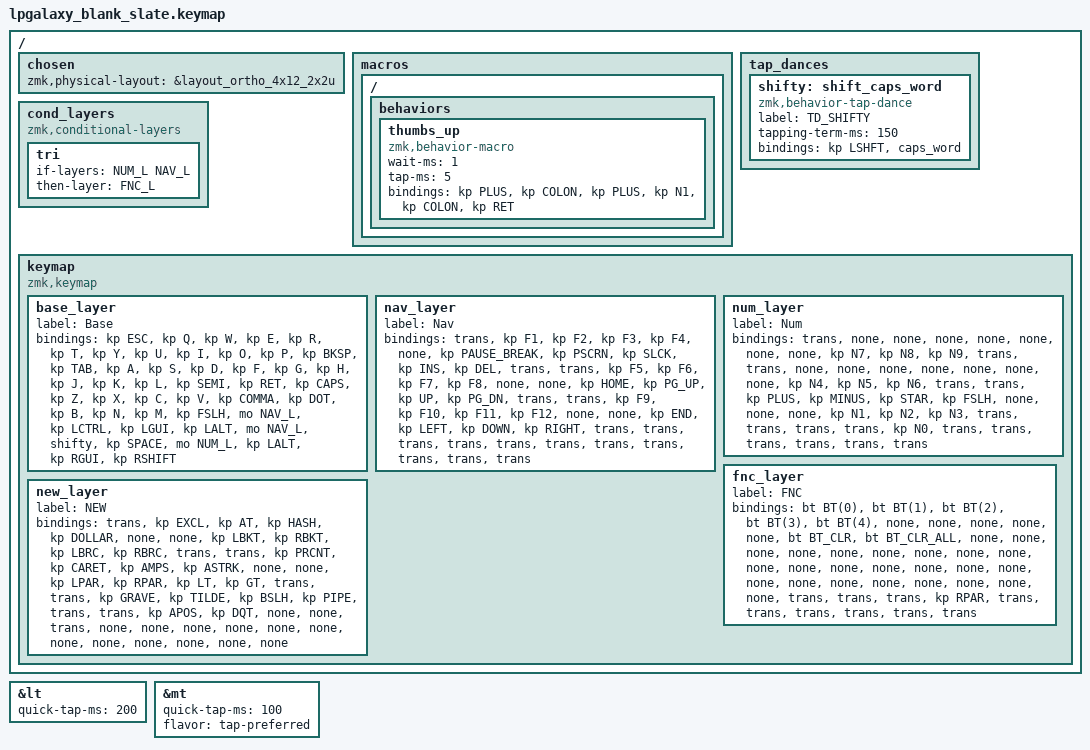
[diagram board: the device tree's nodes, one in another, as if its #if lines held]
/*
 * Copyright (c) 2022 Pete Johanson
 *
 * SPDX-License-Identifier: MIT
 */

#include <behaviors.dtsi>
#include <dt-bindings/zmk/keys.h>
#include <dt-bindings/zmk/bt.h>
#include <dt-bindings/zmk/outputs.h>

#define QWERTY_BASE 1

#define TBLE_ORTHO   1
// #define TBLE_MIT     1
// #define TBLE_DUAL_2U 1

#define NAV_L 1
#define NUM_L 2
#define FNC_L 3
#define NEW_L 4


// Using layer taps on thumbs, having quick tap as well helps w/ repeating space/backspace
&lt { quick-tap-ms = <200>; };
&mt { quick-tap-ms = <100>; flavor = "tap-preferred"; };

#define BT(n) BT_SEL n

/ {
    chosen {
       zmk,physical-layout =
#ifdef TBLE_DUAL_2U
                       &layout_ortho_4x12_2x2u;
#elif defined(TBLE_MIT)
                       &layout_ortho_4x12_1x2u;
#else
                       &layout_ortho_4x12_all1u;
#endif
    };

    macros {
      ZMK_MACRO(thumbs_up,
		wait-ms = <1>;
		tap-ms = <5>;
                bindings = <&kp PLUS &kp COLON &kp PLUS &kp N1 &kp COLON &kp RET>;
		)
    };
    
    tap_dances {
    	shifty: shift_caps_word {
		compatible = "zmk,behavior-tap-dance";
		label = "TD_SHIFTY";
		#binding-cells = <0>;
		tapping-term-ms = <150>;
		bindings = <&kp LSHFT>, <&caps_word>;
	};
    };


// Conditional layer only when we have less thumb keys
#ifdef TBLE_DUAL_2U
    cond_layers {
        compatible = "zmk,conditional-layers";
	tri {
	    if-layers = <NUM_L NAV_L>;
	    then-layer = <FNC_L>;
        };
    };
#endif

    keymap {
        compatible = "zmk,keymap";

        base_layer {
            label = "Base";
            bindings = <
#ifdef QWERTY_BASE 
		 &kp ESC    &kp Q      &kp W      &kp E     &kp R    &kp T       &kp Y     &kp U     &kp I      &kp O    &kp P       &kp BKSP     
		 &kp TAB    &kp A      &kp S      &kp D     &kp F    &kp G       &kp H     &kp J     &kp K      &kp L    &kp SEMI    &kp RET
		 &kp CAPS   &kp Z      &kp X      &kp C     &kp V    &kp COMMA   &kp DOT   &kp B     &kp N      &kp M    &kp FSLH    &mo NAV_L
#else
 &kp ESC    &kp Q      &kp W      &kp F       &kp P          &kp B          &kp J            &kp L          &kp U       &kp Y      &kp QUOT      &kp BKSP
 &kp TAB    &kp A      &kp R      &kp S       &kp T          &kp G          &kp M            &kp N          &kp E       &kp I      &kp O         &kp QUOT
 &kp LSHFT  &kp Z      &kp X      &kp C       &kp D          &kp V          &kp K            &kp H          &kp COMMA   &kp DOT    &kp SEMI      &kp RET
#endif
#ifdef TBLE_DUAL_2U
 &kp LCTRL  &kp LGUI   &kp LALT   &mo NAV_L         &shifty                        &kp SPACE                &mo NUM_L   &kp LALT   &kp RGUI      &kp RSHIFT
#elif defined(TBLE_MIT)
 &kp LCTRL  &mo FNC_L   &kp LGUI  &kp LALT    &mo NAV_L          &kp SPACE                   &mo NUM_L      &kp LEFT    &kp UP     &kp DOWN      &kp RIGHT
#else
		 &kp LCTRL  &kp LGUI   &kp LALT    &kp LANG2   &mo NUM_L   &kp SPACE   &kp LSHIFT      &mo NEW_L    &kp LANG1   &kp RALT   &kp RGUI   &kp RCTRL   
#endif
            >;
        };

        nav_layer {
            label = "Nav";
            bindings = <
		&trans      &kp F1      &kp F2      &kp F3      &kp F4      &none    &kp PAUSE_BREAK  &kp PSCRN   &kp SLCK     &kp INS      &kp DEL       &trans
		&trans      &kp F5      &kp F6      &kp F7      &kp F8      &none    &none            &kp HOME    &kp PG_UP    &kp UP       &kp PG_DN     &trans
		&trans      &kp F9      &kp F10     &kp F11     &kp F12     &none    &none            &kp END     &kp LEFT     &kp DOWN     &kp RIGHT     &trans
#ifdef TBLE_DUAL_2U
&trans  &trans        &trans     &trans              &trans                    &trans       &trans         &trans &trans &trans
#elif defined(TBLE_MIT)
&trans  &trans        &trans     &trans      &trans                &trans             &trans      &trans   &trans &trans &trans
#else
		&trans      &trans      &trans      &trans      &trans     &trans    &trans     &trans    &kp K_APP       &trans       &trans    &trans
#endif
            >;
        };

        num_layer {
            label = "Num";
            bindings = <
		&trans     &none      &none      &none      &none      &none     &none     &none     &kp N7    &kp N8     &kp N9      &trans
		&trans     &none      &none      &none      &none      &none     &none     &none     &kp N4    &kp N5     &kp N6      &trans
		&trans     &kp PLUS   &kp MINUS  &kp STAR   &kp FSLH   &none     &none     &none     &kp N1    &kp N2     &kp N3      &trans
#ifdef TBLE_DUAL_2U
&trans  &trans       &trans     &kp N0              &trans                 &trans            &trans         &trans &trans &trans
#elif defined(TBLE_MIT)
&trans  &trans       &trans     &kp N0      &trans           &none            &trans        &kp DEL      &trans &trans &trans
#else			
		&trans     &trans     &trans      &none     &trans     &trans      &trans     &mo FNC_L      &kp N0    &kp DOT   &kp EQUAL    &trans   
#endif
            >;
        };

        fnc_layer {
            label = "FNC";
            bindings = <
		&bt BT(0)    &bt BT(1)    &bt BT(2)     &bt BT(3)     &bt BT(4)     &none        &none      &none      &none      &none       &bt BT_CLR      &bt BT_CLR_ALL
		&none        &none        &none         &none         &none         &none        &none      &none      &none      &none       &none     &none
		&none        &none        &none         &none         &none         &none        &none      &none      &none      &none       &none     &none
#ifdef TBLE_DUAL_2U
&trans &trans        &trans     &kp RPAR                &trans                    &trans       &trans         &trans &trans &trans
#elif defined(TBLE_MIT)
&trans &trans        &trans     &kp RPAR        &trans                &trans             &trans      &trans   &trans &trans &trans
#else
       &none   &none     &none     &none         &none         &none         &none        &none        &none      &none      &studio_unlock   &bootloader
#endif
            >;
        };

        new_layer {
            label = "NEW";
            bindings = <
		&trans     &kp EXCL     &kp AT      &kp HASH    &kp DOLLAR   &none      &none       &kp LBKT    &kp RBKT    &kp LBRC   &kp RBRC    &trans
		&trans     &kp PRCNT    &kp CARET   &kp AMPS    &kp ASTRK    &none      &none       &kp LPAR    &kp RPAR    &kp LT     &kp GT      &trans
		&trans     &kp GRAVE    &kp TILDE   &kp BSLH    &kp PIPE     &trans     &trans      &kp APOS   &kp DQT      &none      &none       &trans
#ifdef TBLE_DUAL_2U
&none    &none     &none      &none       &none      &none      &none     &none      &none      &none      &none     &none
#elif defined(TBLE_MIT)
&none    &none     &none      &none       &none      &none      &none     &none      &none      &none      &none     &none
#else
		&trans    &trans     &trans     &none      &mo FNC_L       &trans      &trans      &trans     &none     &trans      &trans      &trans
#endif
            >;
        };


    };
};
